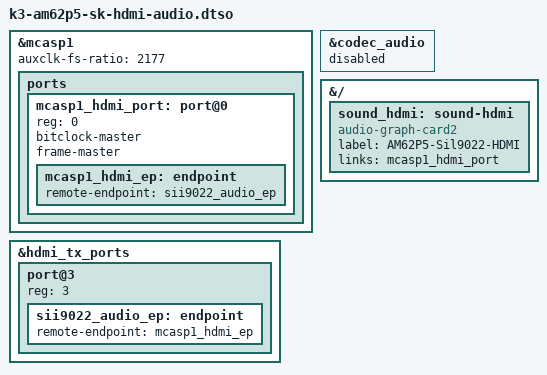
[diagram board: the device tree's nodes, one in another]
// SPDX-License-Identifier: GPL-2.0-only OR MIT
/**
 * DT overlay for HDMI audio on AM62P5-SK via McASP1 and SiI9022A.
 *
 * Copyright (C) 2026 Texas Instruments Incorporated - https://www.ti.com/
 */

/dts-v1/;
/plugin/;

&mcasp1 {
	auxclk-fs-ratio = <2177>;

	ports {
		#address-cells = <1>;
		#size-cells = <0>;

		mcasp1_hdmi_port: port@0 {
			reg = <0>;
			bitclock-master;
			frame-master;

			mcasp1_hdmi_ep: endpoint {
				remote-endpoint = <&sii9022_audio_ep>;
			};
		};
	};
};

&hdmi_tx_ports {
	#address-cells = <1>;
	#size-cells = <0>;

	port@3 {
		reg = <3>;

		sii9022_audio_ep: endpoint {
			remote-endpoint = <&mcasp1_hdmi_ep>;
		};
	};
};

&codec_audio {
	status = "disabled";
};

&{/} {
	sound_hdmi: sound-hdmi {
		compatible = "audio-graph-card2";
		label = "AM62P5-Sil9022-HDMI";
		links = <&mcasp1_hdmi_port>;
	};
};
